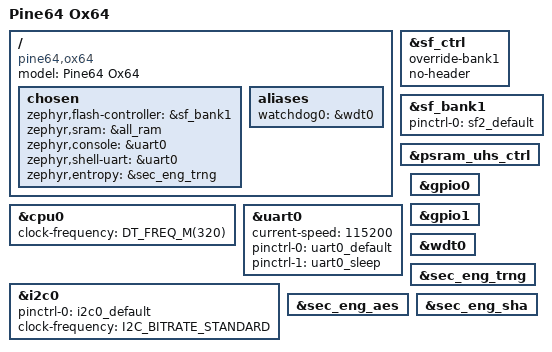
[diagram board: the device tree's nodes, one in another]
/*
 * Copyright (c) 2026 MASSDRIVER EI (massdriver.space)
 *
 * SPDX-License-Identifier: Apache-2.0
 */

#include <bflb/bl808.dtsi>
#include "ox64-pinctrl.dtsi"

/ {
	model = "Pine64 Ox64";
	compatible = "pine64,ox64";

	chosen {
		zephyr,flash-controller = &sf_bank1;
		zephyr,sram = &all_ram;
		zephyr,console = &uart0;
		zephyr,shell-uart = &uart0;
		zephyr,entropy = &sec_eng_trng;
	};

	aliases {
		watchdog0 = &wdt0;
	};
};

&sf_ctrl {
	override-bank1;
	no-header;
};

&sf_bank1 {
	pinctrl-0 = <&sf2_default>;
	pinctrl-names = "default";
};

&psram_uhs_ctrl {
	status = "okay";
};

&cpu0 {
	clock-frequency = <DT_FREQ_M(320)>;
};

&uart0 {
	status = "okay";
	current-speed = <115200>;

	pinctrl-0 = <&uart0_default>;
	pinctrl-1 = <&uart0_sleep>;
	pinctrl-names = "default", "sleep";
};

&i2c0 {
	status = "okay";
	pinctrl-0 = <&i2c0_default>;
	pinctrl-names = "default";
	clock-frequency = <I2C_BITRATE_STANDARD>;
};

&gpio0 {
	status = "okay";
};

&gpio1 {
	status = "okay";
};

&wdt0 {
	status = "okay";
};

&sec_eng_trng {
	status = "okay";
};

&sec_eng_aes {
	status = "okay";
};

&sec_eng_sha {
	status = "okay";
};
